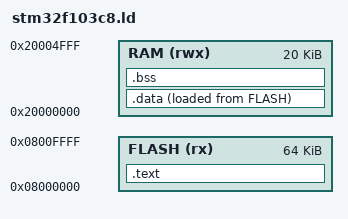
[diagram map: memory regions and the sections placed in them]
MEMORY
{
  FLASH (rx)      : ORIGIN = 0x08000000, LENGTH = 64K
  RAM (rwx)       : ORIGIN = 0x20000000, LENGTH = 20K
}

_estack = ORIGIN(RAM) + LENGTH(RAM);

ENTRY(Reset_Handler)

SECTIONS
{
  .text :
  {
    . = ALIGN(4);
    KEEP(*(.isr_vector))
    *(.text*)
    *(.rodata*)
    . = ALIGN(4);
    _etext = .;
  } > FLASH

  .data :
  {
    . = ALIGN(4);
    _sidata = LOADADDR(.data);
    _sdata = .;
    *(.data*)
    . = ALIGN(4);
    _edata = .;
  } > RAM AT > FLASH

  .bss :
  {
    . = ALIGN(4);
    _sbss = .;
    *(.bss*)
    *(COMMON)
    . = ALIGN(4);
    _ebss = .;
  } > RAM

  /DISCARD/ :
  {
    *(.note*)
    *(.comment*)
  }
}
